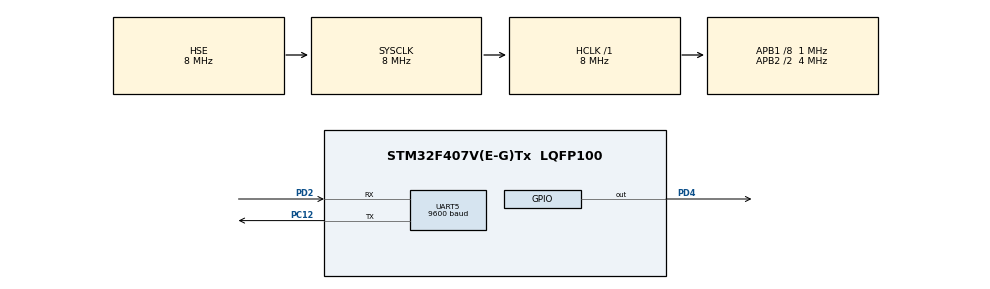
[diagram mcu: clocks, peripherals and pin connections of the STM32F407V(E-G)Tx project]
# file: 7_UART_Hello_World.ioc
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Mcu.Family=STM32F4
Mcu.Name=STM32F407V(E-G)Tx
Mcu.Package=LQFP100
NVIC.PriorityGroup=NVIC_PRIORITYGROUP_0
PA13.Mode=Serial_Wire
PA13.Signal=SYS_JTMS-SWDIO
PA14.Mode=Serial_Wire
PA14.Signal=SYS_JTCK-SWCLK
PC12.Mode=Asynchronous
PC12.Signal=UART5_TX
PD2.Mode=Asynchronous
PD2.Signal=UART5_RX
PD4.GPIO_PuPd=GPIO_PULLDOWN
PD4.Signal=GPIO_Output
PH0-OSC_IN.Mode=HSE-External-Oscillator
PH0-OSC_IN.Signal=RCC_OSC_IN
PH1-OSC_OUT.Mode=HSE-External-Oscillator
PH1-OSC_OUT.Signal=RCC_OSC_OUT
ProjectManager.HeapSize=0x200
ProjectManager.StackSize=0x400
ProjectManager.TargetToolchain=STM32CubeIDE
RCC.48MHZClocksFreq_Value=14285714.285714285
RCC.AHBFreq_Value=8000000
RCC.APB1CLKDivider=RCC_HCLK_DIV8
RCC.APB1Freq_Value=1000000
RCC.APB1TimFreq_Value=2000000
RCC.APB2CLKDivider=RCC_HCLK_DIV2
RCC.APB2Freq_Value=4000000
RCC.APB2TimFreq_Value=8000000
RCC.CortexFreq_Value=8000000
RCC.HCLKFreq_Value=8000000
RCC.HSE_VALUE=8000000
RCC.HSI_VALUE=16000000
RCC.PLLM=8
RCC.PLLN=50
RCC.PLLP=RCC_PLLP_DIV4
RCC.PLLQ=7
RCC.SYSCLKFreq_VALUE=8000000
RCC.SYSCLKSource=RCC_SYSCLKSOURCE_HSE
RCC.VCOOutputFreq_Value=100000000
UART5.BaudRate=9600
UART5.VirtualMode=Asynchronous
board=STM32F407G-DISC1

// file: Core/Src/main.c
/* USER CODE BEGIN Header */
/**
  ******************************************************************************
  * @file           : main.c
  * @brief          : Main program body
  ******************************************************************************
  * @attention
  *
  * Copyright (c) 2024 STMicroelectronics.
  * All rights reserved.
  *
  * This software is licensed under terms that can be found in the LICENSE file
  * in the root directory of this software component.
  * If no LICENSE file comes with this software, it is provided AS-IS.
  *
  ******************************************************************************
  */
/* USER CODE END Header */
#include "main.h"

/* USER CODE BEGIN PD */

#define one_second 	1000
#define onehundred_milisecond 	1000

/* USER CODE END PD */

UART_HandleTypeDef huart5;

/* USER CODE BEGIN PV */
unsigned char data[12] = "Hello World";
uint8_t data_length = 0;
/* USER CODE END PV */

void SystemClock_Config(void);
static void MX_GPIO_Init(void);
static void MX_UART5_Init(void);

int main(void)
{

  /* MCU Configuration--------------------------------------------------------*/

  /* Reset of all peripherals, Initializes the Flash interface and the Systick. */
  HAL_Init();

  /* Configure the system clock */
  SystemClock_Config();

  /* Initialize all configured peripherals */
  MX_GPIO_Init();
  MX_UART5_Init();

  /* Infinite loop */
  /* USER CODE BEGIN WHILE */
  while (1)
  {
	  HAL_GPIO_WritePin(GPIOD, GPIO_PIN_4, 1);
	  HAL_UART_Transmit(&huart5, data, sizeof(data), HAL_MAX_DELAY);
	  HAL_GPIO_WritePin(GPIOD, GPIO_PIN_4, 0);
	  HAL_Delay(onehundred_milisecond);

    /* USER CODE END WHILE */

  }
}

void SystemClock_Config(void)
{
  RCC_OscInitTypeDef RCC_OscInitStruct = {0};
  RCC_ClkInitTypeDef RCC_ClkInitStruct = {0};

  /** Configure the main internal regulator output voltage
  */
  __HAL_RCC_PWR_CLK_ENABLE();
  __HAL_PWR_VOLTAGESCALING_CONFIG(PWR_REGULATOR_VOLTAGE_SCALE1);

  /** Initializes the RCC Oscillators according to the specified parameters
  * in the RCC_OscInitTypeDef structure.
  */
  RCC_OscInitStruct.OscillatorType = RCC_OSCILLATORTYPE_HSE;
  RCC_OscInitStruct.HSEState = RCC_HSE_ON;
  RCC_OscInitStruct.PLL.PLLState = RCC_PLL_NONE;
  if (HAL_RCC_OscConfig(&RCC_OscInitStruct) != HAL_OK)
  {
    Error_Handler();
  }

  /** Initializes the CPU, AHB and APB buses clocks
  */
  RCC_ClkInitStruct.ClockType = RCC_CLOCKTYPE_HCLK|RCC_CLOCKTYPE_SYSCLK
                              |RCC_CLOCKTYPE_PCLK1|RCC_CLOCKTYPE_PCLK2;
  RCC_ClkInitStruct.SYSCLKSource = RCC_SYSCLKSOURCE_HSE;
  RCC_ClkInitStruct.AHBCLKDivider = RCC_SYSCLK_DIV1;
  RCC_ClkInitStruct.APB1CLKDivider = RCC_HCLK_DIV8;
  RCC_ClkInitStruct.APB2CLKDivider = RCC_HCLK_DIV2;

  if (HAL_RCC_ClockConfig(&RCC_ClkInitStruct, FLASH_LATENCY_0) != HAL_OK)
  {
    Error_Handler();
  }
}

static void MX_UART5_Init(void)
{

  huart5.Instance = UART5;
  huart5.Init.BaudRate = 9600;
  huart5.Init.WordLength = UART_WORDLENGTH_8B;
  huart5.Init.StopBits = UART_STOPBITS_1;
  huart5.Init.Parity = UART_PARITY_NONE;
  huart5.Init.Mode = UART_MODE_TX_RX;
  huart5.Init.HwFlowCtl = UART_HWCONTROL_NONE;
  huart5.Init.OverSampling = UART_OVERSAMPLING_16;
  if (HAL_UART_Init(&huart5) != HAL_OK)
  {
    Error_Handler();
  }

}

static void MX_GPIO_Init(void)
{
  GPIO_InitTypeDef GPIO_InitStruct = {0};

  /* GPIO Ports Clock Enable */
  __HAL_RCC_GPIOH_CLK_ENABLE();
  __HAL_RCC_GPIOA_CLK_ENABLE();
  __HAL_RCC_GPIOC_CLK_ENABLE();
  __HAL_RCC_GPIOD_CLK_ENABLE();

  /*Configure GPIO pin Output Level */
  HAL_GPIO_WritePin(GPIOD, GPIO_PIN_4, GPIO_PIN_RESET);

  /*Configure GPIO pin : PD4 */
  GPIO_InitStruct.Pin = GPIO_PIN_4;
  GPIO_InitStruct.Mode = GPIO_MODE_OUTPUT_PP;
  GPIO_InitStruct.Pull = GPIO_PULLDOWN;
  GPIO_InitStruct.Speed = GPIO_SPEED_FREQ_LOW;
  HAL_GPIO_Init(GPIOD, &GPIO_InitStruct);

}

void Error_Handler(void)
{
  __disable_irq();
  while (1)
  {
  }
}
